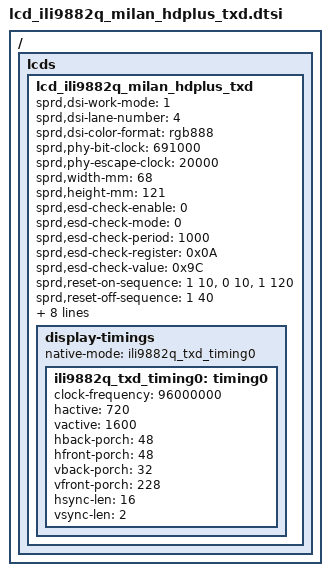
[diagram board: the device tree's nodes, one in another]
/ {
	fragment {
		target-path = "/";
		__overlay__ {
			lcds {
				lcd_ili9882q_milan_hdplus_txd: lcd_ili9882q_milan_hdplus_txd {

					sprd,dsi-work-mode = <1>;
					sprd,dsi-lane-number = <4>;
					sprd,dsi-color-format = "rgb888";

					sprd,phy-bit-clock = <691000>;
					sprd,phy-escape-clock = <20000>;

					sprd,width-mm = <68>;
					sprd,height-mm = <121>;

					sprd,esd-check-enable = <0>;
					sprd,esd-check-mode = <0>;  /*Read register*/
					sprd,esd-check-period = <1000>;
					sprd,esd-check-register = <0x0A>;
					sprd,esd-check-value = <0x9C>;

					sprd,reset-on-sequence = <1 10>, <0 10>, <1 120>;
					sprd,reset-off-sequence = <1 40>;

					sprd,initial-command = [
						39 00 00 04 FF 98 82 01
						23 00 00 02 00 44
						23 00 00 02 01 13
						23 00 00 02 02 10
						23 00 00 02 03 20
						23 00 00 02 04 CA
						23 00 00 02 05 13
						23 00 00 02 06 10
						23 00 00 02 07 20
						23 00 00 02 08 82
						23 00 00 02 09 09
						23 00 00 02 0a b3
						23 00 00 02 0b 00
						23 00 00 02 0c 17
						23 00 00 02 0d 17
						23 00 00 02 0e 04
						23 00 00 02 0f 04
						23 00 00 02 10 0A
						23 00 00 02 11 0A
						23 00 00 02 12 09
						23 00 00 02 1E 0A
						23 00 00 02 1F 0A
						23 00 00 02 16 82
						23 00 00 02 17 09
						23 00 00 02 18 33
						23 00 00 02 19 00
						23 00 00 02 1a 17
						23 00 00 02 1b 17
						23 00 00 02 1c 04
						23 00 00 02 1d 04
						23 00 00 02 20 09
						23 00 00 02 24 02
						23 00 00 02 25 0b
						23 00 00 02 26 10
						23 00 00 02 27 20
						23 00 00 02 2c 34
						23 00 00 02 31 07
						23 00 00 02 32 2a
						23 00 00 02 33 2a
						23 00 00 02 34 0D
						23 00 00 02 35 28
						23 00 00 02 36 29
						23 00 00 02 37 11
						23 00 00 02 38 13
						23 00 00 02 39 15
						23 00 00 02 3a 17
						23 00 00 02 3b 19
						23 00 00 02 3c 1b
						23 00 00 02 3d 09
						23 00 00 02 3e 07
						23 00 00 02 3f 07
						23 00 00 02 40 07
						23 00 00 02 41 07
						23 00 00 02 42 07
						23 00 00 02 43 07
						23 00 00 02 44 07
						23 00 00 02 45 07
						23 00 00 02 46 07
						23 00 00 02 47 07
						23 00 00 02 48 2a
						23 00 00 02 49 2a
						23 00 00 02 4a 0C
						23 00 00 02 4b 28
						23 00 00 02 4c 29
						23 00 00 02 4d 10
						23 00 00 02 4e 12
						23 00 00 02 4f 14
						23 00 00 02 50 16
						23 00 00 02 51 18
						23 00 00 02 52 1a
						23 00 00 02 53 08
						23 00 00 02 54 07
						23 00 00 02 55 07
						23 00 00 02 56 07
						23 00 00 02 57 07
						23 00 00 02 58 07
						23 00 00 02 59 07
						23 00 00 02 5a 07
						23 00 00 02 5b 07
						23 00 00 02 5c 07
						23 00 00 02 61 07
						23 00 00 02 62 2a
						23 00 00 02 63 2a
						23 00 00 02 64 0D
						23 00 00 02 65 28
						23 00 00 02 66 29
						23 00 00 02 67 11
						23 00 00 02 68 13
						23 00 00 02 69 15
						23 00 00 02 6a 17
						23 00 00 02 6b 19
						23 00 00 02 6c 1b
						23 00 00 02 6d 09
						23 00 00 02 6e 07
						23 00 00 02 6f 07
						23 00 00 02 70 07
						23 00 00 02 71 07
						23 00 00 02 72 07
						23 00 00 02 73 07
						23 00 00 02 74 07
						23 00 00 02 75 07
						23 00 00 02 76 07
						23 00 00 02 77 07
						23 00 00 02 78 2a
						23 00 00 02 79 2a
						23 00 00 02 7a 0C
						23 00 00 02 7b 28
						23 00 00 02 7c 29
						23 00 00 02 7d 10
						23 00 00 02 7e 12
						23 00 00 02 7f 14
						23 00 00 02 80 16
						23 00 00 02 81 18
						23 00 00 02 82 1a
						23 00 00 02 83 08
						23 00 00 02 84 07
						23 00 00 02 85 07
						23 00 00 02 86 07
						23 00 00 02 87 07
						23 00 00 02 88 07
						23 00 00 02 89 07
						23 00 00 02 8a 07
						23 00 00 02 8b 07
						23 00 00 02 8c 07
						23 00 00 02 A0 01
						23 00 00 02 A2 00
						23 00 00 02 A3 00
						23 00 00 02 A4 00
						23 00 00 02 A5 00
						23 00 00 02 A6 00
						23 00 00 02 A7 00
						23 00 00 02 A8 00
						23 00 00 02 A9 04
						23 00 00 02 AA 04
						23 00 00 02 AB 00
						23 00 00 02 AC 00
						23 00 00 02 AD 04
						23 00 00 02 AE 04
						23 00 00 02 B0 33
						23 00 00 02 B1 33
						23 00 00 02 B2 00
						23 00 00 02 B9 40
						23 00 00 02 C3 FF
						23 00 00 02 CA 44
						23 00 00 02 D0 01
						23 00 00 02 D1 00
						23 00 00 02 DC 37
						23 00 00 02 DD 42
						23 00 00 02 E2 00
						23 00 00 02 E6 23
						23 00 00 02 E7 54
						23 00 00 02 ED 00
						39 00 00 04 FF 98 82 02
						23 00 00 02 F1 1C
						23 00 00 02 4B 5A
						23 00 00 02 50 CA
						23 00 00 02 51 00
						23 00 00 02 06 8F
						23 00 00 02 0B A0
						23 00 00 02 0C 00
						23 00 00 02 0D 12
						23 00 00 02 0E E4
						23 00 00 02 4E 11
						23 00 00 02 4D CE
						23 00 00 02 F2 4A
						39 00 00 04 FF 98 82 05
						23 00 00 02 03 01
						23 00 00 02 04 13
						23 00 00 02 47 0A
						23 00 00 02 85 77
						23 00 00 02 63 9C
						23 00 00 02 64 9C
						23 00 00 02 68 8D
						23 00 00 02 69 93
						23 00 00 02 6A C9
						23 00 00 02 6B BB
						23 00 00 02 C8 8D
						23 00 00 02 C9 8D
						23 00 00 02 CA 8D
						23 00 00 02 CB 4D
						23 00 00 02 D0 93
						23 00 00 02 D1 93
						23 00 00 02 D2 93
						23 00 00 02 D3 53
						39 00 00 04 FF 98 82 06
						23 00 00 02 D9 1F
						23 00 00 02 C0 40
						23 00 00 02 C1 16
						23 00 00 02 80 09
						39 00 00 04 FF 98 82 07
						23 00 00 02 C0 01
						23 00 00 02 CB CF
						23 00 00 02 CC B0
						23 00 00 02 CD 9D
						23 00 00 02 CE 7E
						39 00 00 04 FF 98 82 08
						39 00 00 1C E0 00 24 52 76 A7 50 D3 F7 24 48 95 83 B4 E0 0A AA 36 6C 8F BC FE E2 15 54 89 03 EC
						39 00 00 1C E1 00 24 52 76 A7 50 D3 F7 24 48 95 83 B4 E0 0A AA 36 6C 8F BC FE E2 15 54 89 03 EC
						39 00 00 04 FF 98 82 0B
						23 00 00 02 9A 89
						23 00 00 02 9B 05
						23 00 00 02 9C 06
						23 00 00 02 9D 06
						23 00 00 02 9E E1
						23 00 00 02 9F E1
						23 00 00 02 AA 22
						23 00 00 02 AB E0
						23 00 00 02 AC 7F
						23 00 00 02 AD 3F
						39 00 00 04 FF 98 82 0E
						23 00 00 02 11 10
						23 00 00 02 12 08
						23 00 00 02 13 10
						23 00 00 02 00 A0
						39 00 00 04 FF 98 82 00
						39 00 00 03 51 ff ff
						23 00 00 02 53 2C
						23 00 00 02 55 00
						23 05 00 02 35 00
						23 78 00 02 11 00
						23 23 00 02 29 00
						];
			sprd,page-unlock-command = [
			39 00 00 03 F0 5A 59  
			39 00 00 03 F1 A5 A6
						];
					sprd,sleep-in-command = [
			23 00 00 02 26 08
			23 23 00 02 28 00
			23 78 00 02 10 00
						];
					sprd,sleep-out-command = [
			23 78 00 02 11 00
			23 23 00 02 29 00
			23 00 00 02 26 01
						];

					display-timings {
						native-mode = <&ili9882q_txd_timing0>;

						ili9882q_txd_timing0: timing0 {
							clock-frequency = <96000000>;
				hactive = <720>;
				vactive = <1600>;
				hback-porch = <48>;
				hfront-porch = <48>;
				vback-porch = <32>;
				vfront-porch = <228>;
				hsync-len = <16>;
				vsync-len = <2>;
						};
					};
					
					
				};
			};
		};
	};
};

